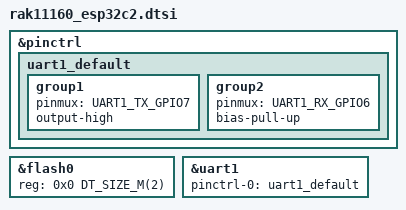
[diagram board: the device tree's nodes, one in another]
/*
 * SPDX-License-Identifier: Apache-2.0
 * Copyright (c) 2026 RAKwireless Technology Limited
 */

#include <espressif/esp32c2/esp32c2.dtsi>
#include <zephyr/dt-bindings/pinctrl/esp32c2-pinctrl.h>

&pinctrl {
	uart1_default: uart1_default {
		group1 {
			pinmux = <UART1_TX_GPIO7>;
			output-high;
		};

		group2 {
			pinmux = <UART1_RX_GPIO6>;
			bias-pull-up;
		};
	};
};

&flash0 {
	reg = <0x0 DT_SIZE_M(2)>;
	ranges = <0x0 0x0 DT_SIZE_M(2)>;
};

&uart1 {
	pinctrl-0 = <&uart1_default>;
	pinctrl-names = "default";
	status = "okay";
};
